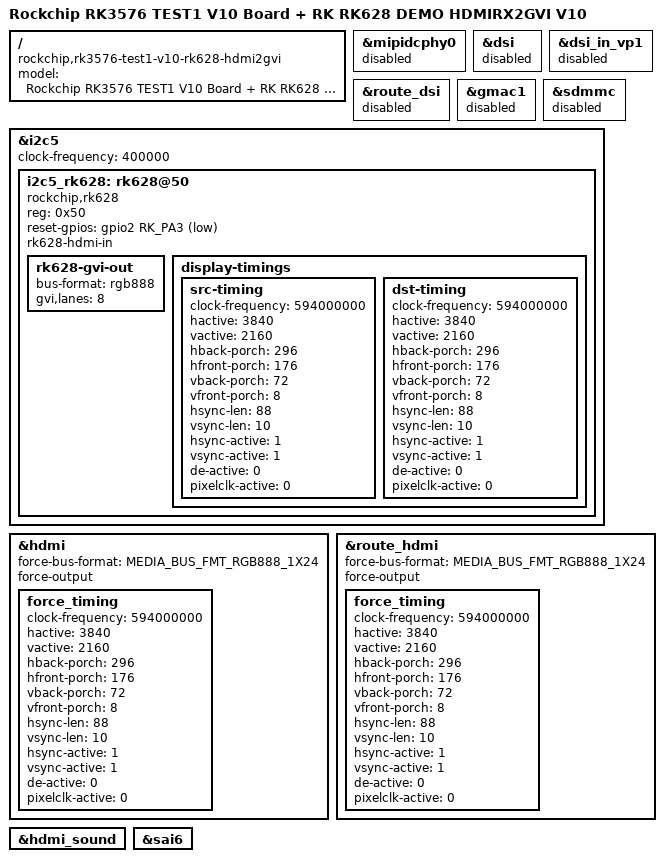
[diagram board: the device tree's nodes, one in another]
// SPDX-License-Identifier: (GPL-2.0+ OR MIT)
/*
 * Copyright (c) 2024 Rockchip Electronics Co., Ltd.
 *
 */

/dts-v1/;

#include <dt-bindings/display/media-bus-format.h>
#include "rk3576.dtsi"
#include "rk3576-test1.dtsi"
#include "rk3576-android.dtsi"

/ {
	model = "Rockchip RK3576 TEST1 V10 Board + RK RK628 DEMO HDMIRX2GVI V10";
	compatible = "rockchip,rk3576-test1-v10-rk628-hdmi2gvi", "rockchip,rk3576";
};

&mipidcphy0 {
	status = "disabled";
};

&dsi {
	status = "disabled";
};

&dsi_in_vp1 {
	status = "disabled";
};

&route_dsi {
	status = "disabled";
};

&gmac1 {
	status = "disabled";
};

&sdmmc {
	status = "disabled";
};

/*
 * rk628
 */

&i2c5 {
	clock-frequency = <400000>;
	status = "okay";

	i2c5_rk628: rk628@50 {
		compatible = "rockchip,rk628";
		reg = <0x50>;
		reset-gpios = <&gpio2 RK_PA3 GPIO_ACTIVE_LOW>;
		status = "okay";

		rk628-hdmi-in;
		rk628-gvi-out {
			/* "rgb666"
			 * "rgb888"
			 * "rgb101010"
			 * "yuyv8"
			 * "yuyv10"
			 */
			bus-format = "rgb888";
			gvi,lanes = <8>;
			//"rockchip,division-mode";
			//"rockchip, gvi-frm-rst";
			status = "okay";
		};

		display-timings {
			src-timing {
				clock-frequency = <594000000>;
				hactive = <3840>;
				vactive = <2160>;
				hback-porch = <296>;
				hfront-porch = <176>;
				vback-porch = <72>;
				vfront-porch = <8>;
				hsync-len = <88>;
				vsync-len = <10>;
				hsync-active = <1>;
				vsync-active = <1>;
				de-active = <0>;
				pixelclk-active = <0>;
			};

			dst-timing {
				clock-frequency = <594000000>;
				hactive = <3840>;
				vactive = <2160>;
				hback-porch = <296>;
				hfront-porch = <176>;
				vback-porch = <72>;
				vfront-porch = <8>;
				hsync-len = <88>;
				vsync-len = <10>;
				hsync-active = <1>;
				vsync-active = <1>;
				de-active = <0>;
				pixelclk-active = <0>;
			};
		};
	};
};

&hdmi {
	status = "okay";
	force-bus-format = <MEDIA_BUS_FMT_RGB888_1X24>;
	force-output;
	force_timing {
		clock-frequency = <594000000>;
		hactive = <3840>;
		vactive = <2160>;
		hback-porch = <296>;
		hfront-porch = <176>;
		vback-porch = <72>;
		vfront-porch = <8>;
		hsync-len = <88>;
		vsync-len = <10>;
		hsync-active = <1>;
		vsync-active = <1>;
		de-active = <0>;
		pixelclk-active = <0>;
	};
};

&route_hdmi {
	status = "okay";
	force-bus-format = <MEDIA_BUS_FMT_RGB888_1X24>;
	force-output;
	force_timing {
		clock-frequency = <594000000>;
		hactive = <3840>;
		vactive = <2160>;
		hback-porch = <296>;
		hfront-porch = <176>;
		vback-porch = <72>;
		vfront-porch = <8>;
		hsync-len = <88>;
		vsync-len = <10>;
		hsync-active = <1>;
		vsync-active = <1>;
		de-active = <0>;
		pixelclk-active = <0>;
	};
};

&hdmi_sound {
	status = "okay";
};

&sai6 {
	status = "okay";
};
